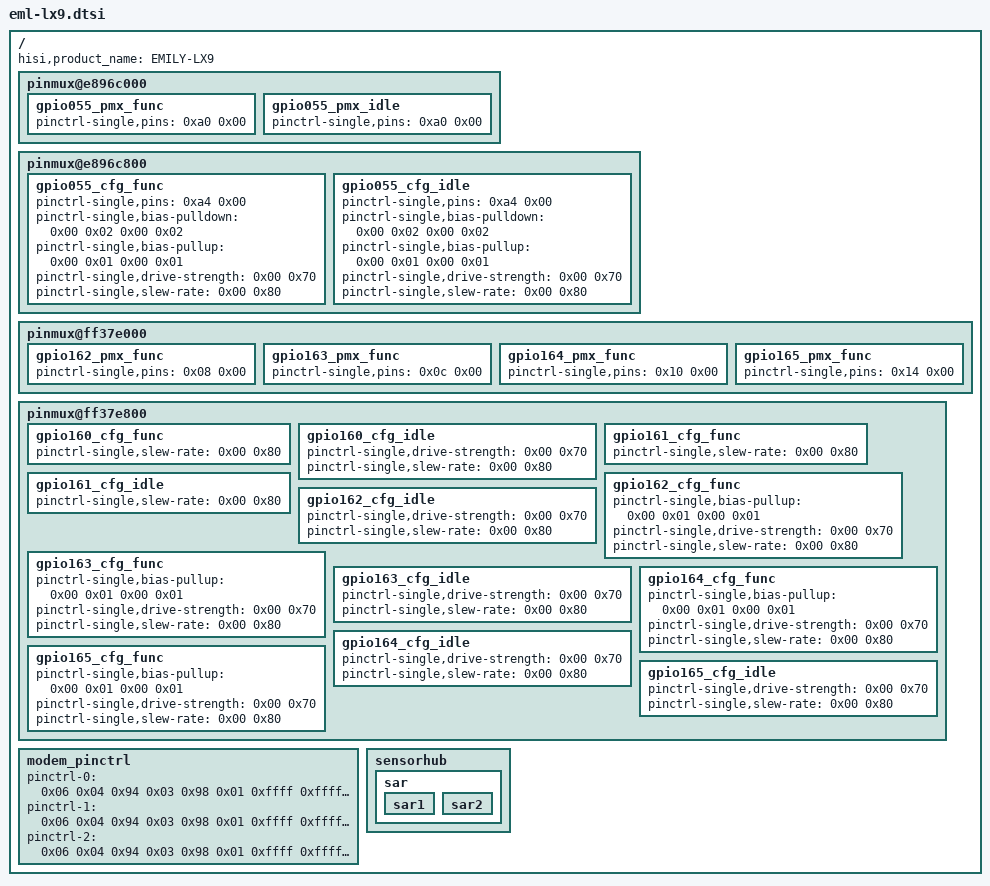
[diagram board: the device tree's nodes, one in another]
/include/ "../eml-common.dtsi"

/ {
	hisi,product_name = "EMILY-LX9";

	pinmux@e896c000 {
		gpio055_pmx_func {
			pinctrl-single,pins = <0xa0 0x00>;
		};

		gpio055_pmx_idle {
			pinctrl-single,pins = <0xa0 0x00>;
		};
	};

	pinmux@e896c800 {
		gpio055_cfg_func {
			pinctrl-single,pins = <0xa4 0x00>;
			pinctrl-single,bias-pulldown = <0x00 0x02 0x00 0x02>;
			pinctrl-single,bias-pullup = <0x00 0x01 0x00 0x01>;
			pinctrl-single,drive-strength = <0x00 0x70>;
			pinctrl-single,slew-rate = <0x00 0x80>;
		};

		gpio055_cfg_idle {
			pinctrl-single,pins = <0xa4 0x00>;
			pinctrl-single,bias-pulldown = <0x00 0x02 0x00 0x02>;
			pinctrl-single,bias-pullup = <0x00 0x01 0x00 0x01>;
			pinctrl-single,drive-strength = <0x00 0x70>;
			pinctrl-single,slew-rate = <0x00 0x80>;
		};
	};

	pinmux@ff37e000 {
		gpio162_pmx_func {
			pinctrl-single,pins = <0x08 0x00>;
		};

		gpio163_pmx_func {
			pinctrl-single,pins = <0x0c 0x00>;
		};

		gpio164_pmx_func {
			pinctrl-single,pins = <0x10 0x00>;
		};

		gpio165_pmx_func {
			pinctrl-single,pins = <0x14 0x00>;
		};
	};

	pinmux@ff37e800 {
		gpio160_cfg_func {
			pinctrl-single,slew-rate = <0x00 0x80>;
		};

		gpio160_cfg_idle {
			pinctrl-single,drive-strength = <0x00 0x70>;
			pinctrl-single,slew-rate = <0x00 0x80>;
		};

		gpio161_cfg_func {
			pinctrl-single,slew-rate = <0x00 0x80>;
		};

		gpio161_cfg_idle {
			pinctrl-single,slew-rate = <0x00 0x80>;
		};

		gpio162_cfg_func {
			pinctrl-single,bias-pullup = <0x00 0x01 0x00 0x01>;
			pinctrl-single,drive-strength = <0x00 0x70>;
			pinctrl-single,slew-rate = <0x00 0x80>;
		};

		gpio162_cfg_idle {
			pinctrl-single,drive-strength = <0x00 0x70>;
			pinctrl-single,slew-rate = <0x00 0x80>;
		};

		gpio163_cfg_func {
			pinctrl-single,bias-pullup = <0x00 0x01 0x00 0x01>;
			pinctrl-single,drive-strength = <0x00 0x70>;
			pinctrl-single,slew-rate = <0x00 0x80>;
		};

		gpio163_cfg_idle {
			pinctrl-single,drive-strength = <0x00 0x70>;
			pinctrl-single,slew-rate = <0x00 0x80>;
		};

		gpio164_cfg_func {
			pinctrl-single,bias-pullup = <0x00 0x01 0x00 0x01>;
			pinctrl-single,drive-strength = <0x00 0x70>;
			pinctrl-single,slew-rate = <0x00 0x80>;
		};

		gpio164_cfg_idle {
			pinctrl-single,drive-strength = <0x00 0x70>;
			pinctrl-single,slew-rate = <0x00 0x80>;
		};

		gpio165_cfg_func {
			pinctrl-single,bias-pullup = <0x00 0x01 0x00 0x01>;
			pinctrl-single,drive-strength = <0x00 0x70>;
			pinctrl-single,slew-rate = <0x00 0x80>;
		};

		gpio165_cfg_idle {
			pinctrl-single,drive-strength = <0x00 0x70>;
			pinctrl-single,slew-rate = <0x00 0x80>;
		};
	};

	modem_pinctrl {
		pinctrl-0 = <0x06 0x04 0x94 0x03 0x98 0x01 0xffff 0xffff 0x06 0x05 0x98 0x03 0x9c 0x00 0xffff 0xffff 0x07 0x02 0xac 0x02 0xb0 0x00 0xffff 0xffff 0x07 0x03 0xb0 0x01 0xb4 0x00 0x01 0x00 0x07 0x04 0xb4 0x01 0xb8 0x00 0x01 0x00 0x07 0x05 0xb8 0x01 0xbc 0x00 0x01 0x00 0x07 0x06 0xbc 0x01 0xc0 0x00 0x01 0x00 0x07 0x07 0xc0 0x01 0xc4 0x00 0x01 0x00 0x08 0x00 0xc4 0x01 0xc8 0x00 0x01 0x00 0x08 0x01 0xc8 0x01 0xcc 0x02 0x01 0x00 0x08 0x02 0xcc 0x01 0xd0 0x00 0xffff 0xffff 0x08 0x03 0xd0 0x01 0xd4 0x00 0xffff 0xffff 0x08 0x04 0xd4 0x01 0xd8 0x00 0xffff 0xffff 0x08 0x05 0xd8 0x01 0xdc 0x00 0xffff 0xffff 0x08 0x06 0xdc 0x01 0xe0 0x00 0xffff 0xffff 0x08 0x07 0xe0 0x01 0xe4 0x00 0xffff 0xffff 0x09 0x00 0xe4 0x01 0xe8 0x00 0xffff 0xffff 0x09 0x01 0xe8 0x01 0xec 0x00 0xffff 0xffff 0x09 0x02 0xec 0x01 0xf0 0x00 0xffff 0xffff 0x09 0x03 0xf0 0x01 0xf4 0x00 0xffff 0xffff 0x09 0x04 0xf4 0x01 0xf8 0x00 0xffff 0xffff 0x09 0x05 0xf8 0x01 0xfc 0x00 0xffff 0xffff 0x09 0x06 0xfc 0x01 0x100 0x00 0xffff 0xffff 0x09 0x07 0x100 0x01 0x104 0x00 0xffff 0xffff 0x0a 0x00 0x104 0x01 0x108 0x00 0xffff 0xffff 0x0a 0x01 0x108 0x01 0x10c 0x00 0xffff 0xffff 0x0a 0x02 0x10c 0x03 0x110 0x00 0xffff 0xffff 0x0a 0x03 0x110 0x03 0x114 0x00 0xffff 0xffff 0x0a 0x04 0x114 0x01 0x118 0x00 0xffff 0xffff 0x0a 0x05 0x118 0x01 0x11c 0x00 0xffff 0xffff 0x0a 0x06 0x11c 0x01 0x120 0x00 0xffff 0xffff 0x0a 0x07 0x120 0x01 0x124 0x00 0xffff 0xffff 0x0b 0x00 0x124 0x01 0x128 0x00 0xffff 0xffff 0x0b 0x01 0x128 0x01 0x12c 0x02 0xffff 0xffff 0x0b 0x02 0x12c 0x01 0x130 0x00 0xffff 0xffff 0x0b 0x03 0x130 0x01 0x134 0x02 0xffff 0xffff 0x0b 0x04 0x134 0x01 0x138 0x00 0xffff 0xffff 0x0b 0x05 0x138 0x01 0x13c 0x00 0xffff 0xffff 0x0b 0x06 0x13c 0x01 0x140 0x00 0xffff 0xffff 0x0b 0x07 0x140 0x01 0x144 0x02 0xffff 0xffff 0x0c 0x00 0x144 0x01 0x148 0x00 0xffff 0xffff 0x12 0x05 0xac 0x03 0xdc 0x00 0xffff 0xffff 0x18 0x05 0x4c 0x00 0x78 0x01 0x00 0xffff>;
		pinctrl-1 = <0x06 0x04 0x94 0x03 0x98 0x01 0xffff 0xffff 0x06 0x05 0x98 0x03 0x9c 0x00 0xffff 0xffff 0x07 0x02 0xac 0x02 0xb0 0x00 0xffff 0xffff 0x07 0x03 0xb0 0x01 0xb4 0x00 0x01 0x00 0x07 0x04 0xb4 0x01 0xb8 0x00 0x01 0x00 0x07 0x05 0xb8 0x01 0xbc 0x00 0x01 0x00 0x07 0x06 0xbc 0x01 0xc0 0x00 0x01 0x00 0x07 0x07 0xc0 0x01 0xc4 0x00 0x01 0x00 0x08 0x00 0xc4 0xffff 0xc8 0xffff 0xffff 0xffff 0x08 0x01 0xc8 0xffff 0xcc 0xffff 0xffff 0xffff 0x08 0x02 0xcc 0x01 0xd0 0x00 0xffff 0xffff 0x08 0x03 0xd0 0x01 0xd4 0x00 0xffff 0xffff 0x08 0x04 0xd4 0x01 0xd8 0x00 0xffff 0xffff 0x08 0x05 0xd8 0x01 0xdc 0x00 0xffff 0xffff 0x08 0x06 0xdc 0x01 0xe0 0x00 0xffff 0xffff 0x08 0x07 0xe0 0x01 0xe4 0x00 0xffff 0xffff 0x09 0x00 0xe4 0x01 0xe8 0x00 0xffff 0xffff 0x09 0x01 0xe8 0x01 0xec 0x00 0xffff 0xffff 0x09 0x02 0xec 0x01 0xf0 0x00 0xffff 0xffff 0x09 0x03 0xf0 0x01 0xf4 0x00 0xffff 0xffff 0x09 0x04 0xf4 0x01 0xf8 0x00 0xffff 0xffff 0x09 0x05 0xf8 0x01 0xfc 0x00 0xffff 0xffff 0x09 0x06 0xfc 0x01 0x100 0x00 0xffff 0xffff 0x09 0x07 0x100 0x01 0x104 0x00 0xffff 0xffff 0x0a 0x00 0x104 0x01 0x108 0x00 0xffff 0xffff 0x0a 0x01 0x108 0x01 0x10c 0x00 0xffff 0xffff 0x0a 0x02 0x10c 0x03 0x110 0x00 0xffff 0xffff 0x0a 0x03 0x110 0x03 0x114 0x00 0xffff 0xffff 0x0a 0x04 0x114 0x01 0x118 0x00 0xffff 0xffff 0x0a 0x05 0x118 0x01 0x11c 0x00 0xffff 0xffff 0x0a 0x06 0x11c 0x01 0x120 0x00 0xffff 0xffff 0x0a 0x07 0x120 0x01 0x124 0x00 0xffff 0xffff 0x0b 0x00 0x124 0x01 0x128 0x00 0xffff 0xffff 0x0b 0x01 0x128 0x01 0x12c 0x02 0xffff 0xffff 0x0b 0x02 0x12c 0x01 0x130 0x00 0xffff 0xffff 0x0b 0x03 0x130 0x01 0x134 0x02 0xffff 0xffff 0x0b 0x04 0x134 0x01 0x138 0x00 0xffff 0xffff 0x0b 0x05 0x138 0x01 0x13c 0x00 0xffff 0xffff 0x0b 0x06 0x13c 0x01 0x140 0x00 0xffff 0xffff 0x0b 0x07 0x140 0x01 0x144 0x02 0xffff 0xffff 0x0c 0x00 0x144 0x01 0x148 0x00 0xffff 0xffff 0x12 0x05 0xac 0x03 0xdc 0x00 0xffff 0xffff 0x18 0x05 0x4c 0xffff 0x78 0xffff 0x00 0xffff>;
		pinctrl-2 = <0x06 0x04 0x94 0x03 0x98 0x01 0xffff 0xffff 0x06 0x05 0x98 0x03 0x9c 0x00 0xffff 0xffff 0x07 0x02 0xac 0x02 0xb0 0x00 0xffff 0xffff 0x07 0x03 0xb0 0x00 0xb4 0x00 0x00 0x00 0x07 0x04 0xb4 0x00 0xb8 0x00 0x00 0x00 0x07 0x05 0xb8 0x00 0xbc 0x00 0x00 0x00 0x07 0x06 0xbc 0x00 0xc0 0x00 0x00 0x00 0x07 0x07 0xc0 0x00 0xc4 0x00 0x00 0x00 0x08 0x00 0xc4 0xffff 0xc8 0xffff 0xffff 0xffff 0x08 0x01 0xc8 0xffff 0xcc 0xffff 0xffff 0xffff 0x08 0x02 0xcc 0x01 0xd0 0x00 0xffff 0xffff 0x08 0x03 0xd0 0x01 0xd4 0x00 0xffff 0xffff 0x08 0x04 0xd4 0x01 0xd8 0x00 0xffff 0xffff 0x08 0x05 0xd8 0x01 0xdc 0x00 0xffff 0xffff 0x08 0x06 0xdc 0x01 0xe0 0x00 0xffff 0xffff 0x08 0x07 0xe0 0x01 0xe4 0x00 0xffff 0xffff 0x09 0x00 0xe4 0x01 0xe8 0x00 0xffff 0xffff 0x09 0x01 0xe8 0x01 0xec 0x00 0xffff 0xffff 0x09 0x02 0xec 0x01 0xf0 0x00 0xffff 0xffff 0x09 0x03 0xf0 0x01 0xf4 0x00 0xffff 0xffff 0x09 0x04 0xf4 0x01 0xf8 0x00 0xffff 0xffff 0x09 0x05 0xf8 0x01 0xfc 0x00 0xffff 0xffff 0x09 0x06 0xfc 0x01 0x100 0x00 0xffff 0xffff 0x09 0x07 0x100 0x01 0x104 0x00 0xffff 0xffff 0x0a 0x00 0x104 0x01 0x108 0x00 0xffff 0xffff 0x0a 0x01 0x108 0x01 0x10c 0x00 0xffff 0xffff 0x0a 0x02 0x10c 0x03 0x110 0x00 0xffff 0xffff 0x0a 0x03 0x110 0x03 0x114 0x00 0xffff 0xffff 0x0a 0x04 0x114 0x01 0x118 0x00 0xffff 0xffff 0x0a 0x05 0x118 0x01 0x11c 0x00 0xffff 0xffff 0x0a 0x06 0x11c 0x01 0x120 0x00 0xffff 0xffff 0x0a 0x07 0x120 0x01 0x124 0x00 0xffff 0xffff 0x0b 0x00 0x124 0x01 0x128 0x00 0xffff 0xffff 0x0b 0x01 0x128 0x01 0x12c 0x02 0xffff 0xffff 0x0b 0x02 0x12c 0x01 0x130 0x00 0xffff 0xffff 0x0b 0x03 0x130 0x01 0x134 0x02 0xffff 0xffff 0x0b 0x04 0x134 0x01 0x138 0x00 0xffff 0xffff 0x0b 0x05 0x138 0x01 0x13c 0x02 0xffff 0xffff 0x0b 0x06 0x13c 0x01 0x140 0x00 0xffff 0xffff 0x0b 0x07 0x140 0x01 0x144 0x02 0xffff 0xffff 0x0c 0x00 0x144 0x01 0x148 0x00 0xffff 0xffff 0x12 0x05 0xac 0x03 0xdc 0x00 0xffff 0xffff 0x18 0x05 0x4c 0xffff 0x78 0xffff 0xffff 0xffff>;
	};

	sensorhub {
		sar {
			sar1 {
				status = "ok";
			};

			sar2 {
				status = "ok";
			};
		};
	};
};
